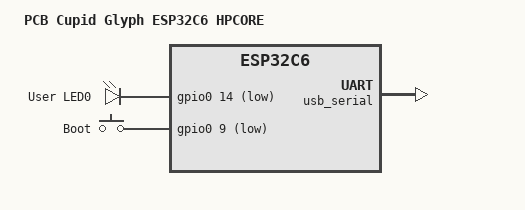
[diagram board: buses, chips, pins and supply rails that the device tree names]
/*
 * Copyright (c) 2023 Espressif Systems (Shanghai) Co., Ltd.
 * Copyright (c) 2025 Muhammed Asif
 *
 * SPDX-License-Identifier: Apache-2.0
 */

/dts-v1/;

#include <espressif/esp32c6/esp32c6_wroom_n4.dtsi>
#include "glyph_c6-pinctrl.dtsi"
#include <zephyr/dt-bindings/input/input-event-codes.h>
#include <espressif/partitions_0x0_default.dtsi>

/ {
	model = "PCB Cupid Glyph ESP32C6 HPCORE";
	compatible = "pcbcupid,glyph-c6";

	chosen {
		zephyr,sram = &sramhp;
		zephyr,console = &usb_serial;
		zephyr,shell-uart = &usb_serial;
		zephyr,flash = &flash0;
		zephyr,code-partition = &slot0_partition;
	};

	aliases {
		led0 = &red_led;
		sw0 = &button0;
	};

	leds: leds {
		compatible = "gpio-leds";

		red_led: led_0 {
			gpios = <&gpio0 14 GPIO_ACTIVE_LOW>;
			label = "User LED0";
		};
	};

	buttons {
		compatible = "gpio-keys";

		button0: button_0 {
			gpios = <&gpio0 9 (GPIO_PULL_UP | GPIO_ACTIVE_LOW)>;
			label = "Boot";
			zephyr,code = <INPUT_KEY_0>;
		};
	};
};

&usb_serial {
	status = "okay";
};

&gpio0 {
	status = "okay";
};
